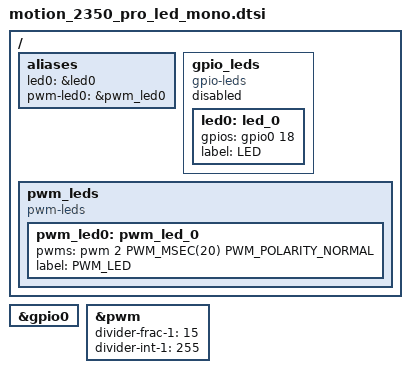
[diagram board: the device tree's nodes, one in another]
/*
 * Copyright (c) 2026 TiaC Systems
 * SPDX-License-Identifier: Apache-2.0
 */

#include <zephyr/dt-bindings/gpio/gpio.h>
#include <zephyr/dt-bindings/pwm/pwm.h>

/ {
	aliases {
		led0 = &led0;
		pwm-led0 = &pwm_led0;
	};

	gpio_leds: gpio_leds {
		compatible = "gpio-leds";
		status = "disabled";

		led0: led_0 {
			gpios = <&gpio0 18 GPIO_ACTIVE_HIGH>;
			label = "LED";
		};
	};

	pwm_leds: pwm_leds {
		compatible = "pwm-leds";
		status = "okay";

		pwm_led0: pwm_led_0 {
			pwms = <&pwm 2 PWM_MSEC(20) PWM_POLARITY_NORMAL>;
			label = "PWM_LED";
		};
	};
};

&gpio0 {
	status = "okay";
};

&pwm {
	divider-frac-1 = <15>;
	divider-int-1 = <255>;
};
